# LargeDummyDevice register map
File version: 1.0
Registers are 32-bit, read-write, no defined reset value unless marked. A register's access mark holds for its fields unless they carry their own. Offsets are from the block's base; [hi:lo] are bit positions.

## PERIPHERAL_49
Base 0x40030000
0x04 REG_1 — Register 1
  [32:31] FIELD_6, [30:27] FIELD_8, [30:26] FIELD_1, [27:25] FIELD_3, [27:25] FIELD_4, [27:24] FIELD_5, [7] FIELD_7, [6] FIELD_2
0x08 REG_2 — Register 2
  [32:29] FIELD_25, [28:25] FIELD_4, [27:25] FIELD_26, [24] FIELD_10, [26:24] FIELD_20, [27:23] FIELD_16, [22] FIELD_13, [25:22] FIELD_28, [21] FIELD_7, [20:19] FIELD_1, [22:19] FIELD_23, [21:18] FIELD_18, [20:16] FIELD_9, [19:15] FIELD_22, [12:11] FIELD_27, [11:10] FIELD_5, [12:10] FIELD_8, [11:10] FIELD_15, [9] FIELD_24, [11:7] FIELD_3, [8:5] FIELD_6, [5] FIELD_12, [9:5] FIELD_19, [4:3] FIELD_17, [1] FIELD_11, [4:1] FIELD_14, [2:0] FIELD_2, [1:0] FIELD_21
0x0C REG_3 — Register 3
  [31:30] FIELD_12, [25] FIELD_3, [22:21] FIELD_8, [22:20] FIELD_1, [21:19] FIELD_7, [22:19] FIELD_9, [21:18] FIELD_2, [16:13] FIELD_10, [13:12] FIELD_5, [12:10] FIELD_13, [11:9] FIELD_11, [1] FIELD_4, [4:1] FIELD_6
0x10 REG_4 — Register 4
  [31] FIELD_1, [27] FIELD_8, [29:25] FIELD_6, [25] FIELD_7, [27:24] FIELD_4, [24] FIELD_15, [24:20] FIELD_19, [21:19] FIELD_24, [21:18] FIELD_11, [20:18] FIELD_25, [18:17] FIELD_21, [18:16] FIELD_2, [18:14] FIELD_20, [14:11] FIELD_10, [13:11] FIELD_13, [10] FIELD_16, [10:8] FIELD_3, [9:8] FIELD_5, [11:7] FIELD_9, [8:6] FIELD_12, [9:6] FIELD_17, [6] FIELD_23, [9:5] FIELD_18, [6:2] FIELD_22, [2] FIELD_26, [3:0] FIELD_14
0x14 REG_5 — Register 5
  [32:28] FIELD_4, [29:26] FIELD_2, [27:24] FIELD_3, [13:11] FIELD_5, [12:9] FIELD_6, [9:8] FIELD_7, [0] FIELD_1
0x18 REG_6 — Register 6
  [31] FIELD_7, [34:30] FIELD_3, [30] FIELD_12, [31:27] FIELD_15, [30:27] FIELD_17, [25] FIELD_8, [25:23] FIELD_18, [24:23] FIELD_21, [22:20] FIELD_9, [22:18] FIELD_16, [18:16] FIELD_10, [15] FIELD_19, [14] FIELD_5, [15:13] FIELD_1, [16:12] FIELD_14, [12:10] FIELD_2, [10] FIELD_11, [9:8] FIELD_13, [10:8] FIELD_20, [9:6] FIELD_4, [7:4] FIELD_6
0x1C REG_7 — Register 7
  [35:31] FIELD_12, [32:29] FIELD_11, [25:21] FIELD_2, [24:20] FIELD_4, [22:20] FIELD_6, [18] FIELD_3, [18] FIELD_10, [14:11] FIELD_8, [9] FIELD_7, [10:7] FIELD_1, [4] FIELD_9, [3:1] FIELD_5
0x20 REG_8 — Register 8
  [32:30] FIELD_14, [32:29] FIELD_2, [29:28] FIELD_5, [22] FIELD_7, [23:22] FIELD_23, [23:19] FIELD_20, [22:18] FIELD_13, [20:17] FIELD_1, [16:14] FIELD_10, [14] FIELD_15, [14:13] FIELD_3, [16:13] FIELD_4, [13] FIELD_25, [14:11] FIELD_12, [15:11] FIELD_22, [9] FIELD_16, [11:9] FIELD_17, [12:9] FIELD_19, [11:9] FIELD_24, [9:8] FIELD_21, [7] FIELD_8, [7] FIELD_11, [10:6] FIELD_6, [7:6] FIELD_9, [6:3] FIELD_18
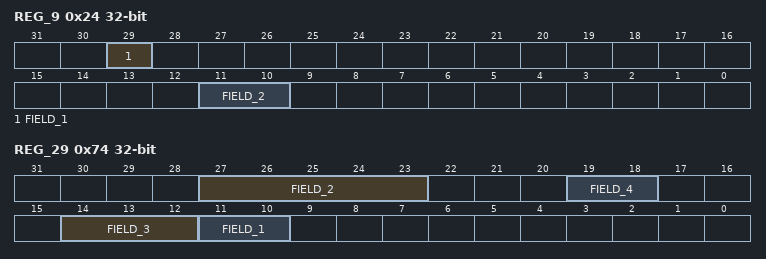
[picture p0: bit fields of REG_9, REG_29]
0x24 REG_9 — Register 9
  [29] FIELD_1, [11:10] FIELD_2
0x28 REG_10 — Register 10
  [34:31] FIELD_21, [30] FIELD_10, [32:30] FIELD_19, [33:29] FIELD_13, [32:28] FIELD_17, [31:27] FIELD_7, [26] FIELD_3, [26] FIELD_4, [26] FIELD_6, [24:23] FIELD_5, [25:22] FIELD_14, [23:21] FIELD_9, [24:21] FIELD_23, [23:21] FIELD_29, [21] FIELD_32, [22:18] FIELD_28, [20:16] FIELD_16, [19:15] FIELD_1, [17:15] FIELD_11, [15:11] FIELD_25, [10] FIELD_27, [13:9] FIELD_8, [10:9] FIELD_30, [9:7] FIELD_26, [7] FIELD_31, [9:6] FIELD_15, [7:6] FIELD_20, [9:5] FIELD_18, [3:2] FIELD_22, [4:2] FIELD_24, [3:0] FIELD_2, [3:0] FIELD_12
0x2C REG_11 — Register 11
  [25:22] FIELD_1
0x30 REG_12 — Register 12
  [26:24] FIELD_2, [27:23] FIELD_3, [23:21] FIELD_5, [17] FIELD_9, [12] FIELD_8, [13:10] FIELD_6, [9] FIELD_4, [11:7] FIELD_7, [8:6] FIELD_1
0x34 REG_13 — Register 13
  [35:31] FIELD_10, [33:30] FIELD_9, [31:30] FIELD_11, [31:29] FIELD_29, [29] FIELD_30, [29:28] FIELD_8, [31:27] FIELD_7, [26:25] FIELD_4, [24:22] FIELD_3, [22] FIELD_6, [23:22] FIELD_25, [17] FIELD_22, [15:14] FIELD_26, [14] FIELD_28, [14:13] FIELD_12, [12] FIELD_31, [15:11] FIELD_23, [13:10] FIELD_1, [13:9] FIELD_16, [10:9] FIELD_19, [9:8] FIELD_5, [9:8] FIELD_13, [7] FIELD_15, [7:5] FIELD_2, [6:5] FIELD_17, [4] FIELD_14, [7:3] FIELD_18, [6:3] FIELD_21, [3] FIELD_27, [3:1] FIELD_24, [0] FIELD_20
0x38 REG_14 — Register 14
  [22] FIELD_4, [15:14] FIELD_3, [13] FIELD_1, [9:7] FIELD_2, [8:6] FIELD_5
0x3C REG_15 — Register 15
  [35:31] FIELD_4, [29] FIELD_16, [23] FIELD_12, [26:22] FIELD_17, [24:21] FIELD_6, [25:21] FIELD_8, [22:21] FIELD_13, [14] FIELD_1, [15:13] FIELD_9, [12] FIELD_7, [14:10] FIELD_10, [7] FIELD_18, [8:6] FIELD_5, [10:6] FIELD_14, [5:4] FIELD_3, [7:3] FIELD_11, [6:3] FIELD_15, [4:2] FIELD_2
0x40 REG_16 — Register 16
  [30:26] FIELD_9, [23:22] FIELD_4, [20:17] FIELD_7, [17:16] FIELD_2, [12] FIELD_8, [13:11] FIELD_1, [11:9] FIELD_6, [8:5] FIELD_5, [4:3] FIELD_11, [3:2] FIELD_3, [2:0] FIELD_10
0x44 REG_17 — Register 17
  [33:31] FIELD_15, [23] FIELD_5, [22:20] FIELD_1, [23:20] FIELD_7, [20:19] FIELD_2, [20:19] FIELD_12, [22:18] FIELD_4, [18:15] FIELD_8, [19:15] FIELD_14, [14] FIELD_6, [17:13] FIELD_9, [13:11] FIELD_13, [10] FIELD_18, [11:10] FIELD_19, [12:10] FIELD_20, [11:9] FIELD_11, [5] FIELD_17, [3] FIELD_3, [4:1] FIELD_10, [3:0] FIELD_16
0x48 REG_18 — Register 18
  [30] FIELD_2, [25] FIELD_3, [23] FIELD_6, [23:22] FIELD_7, [20:19] FIELD_8, [18:17] FIELD_1, [9:6] FIELD_4, [3:1] FIELD_5
0x4C REG_19 — Register 19
  [33:30] FIELD_10, [29:27] FIELD_7, [26] FIELD_2, [29:25] FIELD_5, [12] FIELD_1, [15:12] FIELD_6, [12:8] FIELD_9, [6:5] FIELD_8, [8:4] FIELD_4, [2:1] FIELD_3
0x50 REG_20 — Register 20
  [33:31] FIELD_7, [25:24] FIELD_6, [18] FIELD_8, [19:16] FIELD_1, [11:9] FIELD_10, [10:8] FIELD_2, [6] FIELD_9, [7:4] FIELD_3, [6:3] FIELD_4, [3] FIELD_5, [2] FIELD_12, [3:1] FIELD_11
0x54 REG_21 — Register 21
  [27] FIELD_16, [28:26] FIELD_10, [28:24] FIELD_6, [27:23] FIELD_20, [24:20] FIELD_2, [19] FIELD_9, [19:15] FIELD_3, [15] FIELD_18, [15:14] FIELD_4, [14] FIELD_14, [15:14] FIELD_19, [16:13] FIELD_5, [13:10] FIELD_7, [7:4] FIELD_8, [8:4] FIELD_13, [5:4] FIELD_17, [6:3] FIELD_15, [4:2] FIELD_11, [4:2] FIELD_12, [5:1] FIELD_1
0x58 REG_22 — Register 22
  [34:31] FIELD_21, [30] FIELD_16, [31:29] FIELD_3, [32:29] FIELD_14, [32:28] FIELD_4, [28] FIELD_8, [29:28] FIELD_12, [31:27] FIELD_23, [28:26] FIELD_18, [28:25] FIELD_10, [23] FIELD_15, [25:21] FIELD_7, [22:18] FIELD_9, [20:17] FIELD_22, [17:14] FIELD_19, [17:14] FIELD_24, [14:13] FIELD_6, [14:13] FIELD_17, [13:12] FIELD_13, [15:11] FIELD_20, [8:6] FIELD_5, [6:3] FIELD_11, [2:1] FIELD_1, [1] FIELD_2
0x5C REG_23 — Register 23
  [33:29] FIELD_4, [28:26] FIELD_5, [17:15] FIELD_3, [14:12] FIELD_1, [16:12] FIELD_2
0x60 REG_24 — Register 24
  [29:28] FIELD_10, [29:27] FIELD_9, [27:26] FIELD_4, [28:24] FIELD_11, [23:20] FIELD_5, [16:14] FIELD_6, [2] FIELD_8, [5:1] FIELD_3, [5:1] FIELD_7, [3:0] FIELD_1, [2:0] FIELD_2
0x64 REG_25 — Register 25
  [31:28] FIELD_2, [30:28] FIELD_3, [24:22] FIELD_1, [22:18] FIELD_4
0x68 REG_26 — Register 26
  [30:29] FIELD_9, [29:28] FIELD_7, [29:28] FIELD_26, [29:25] FIELD_16, [24] FIELD_11, [25:24] FIELD_23, [26:23] FIELD_5, [24:23] FIELD_25, [25:23] FIELD_27, [23:21] FIELD_21, [22:20] FIELD_2, [22:20] FIELD_14, [18] FIELD_13, [18:16] FIELD_4, [20:16] FIELD_24, [16] FIELD_30, [19:15] FIELD_6, [17:15] FIELD_10, [18:14] FIELD_3, [13:12] FIELD_12, [16:12] FIELD_19, [15:11] FIELD_15, [15:11] FIELD_29, [13:9] FIELD_22, [10:9] FIELD_28, [11:8] FIELD_17, [9:7] FIELD_18, [6] FIELD_31, [8:4] FIELD_1, [5:1] FIELD_20, [2:0] FIELD_8
0x6C REG_27 — Register 27
  [33:30] FIELD_3, [33:30] FIELD_25, [30:28] FIELD_6, [27:23] FIELD_1, [25:23] FIELD_16, [22:21] FIELD_18, [23:20] FIELD_10, [19] FIELD_12, [20:19] FIELD_21, [18:17] FIELD_2, [18:15] FIELD_11, [17:15] FIELD_20, [17:13] FIELD_4, [14:12] FIELD_13, [15:12] FIELD_22, [13:11] FIELD_17, [12:11] FIELD_19, [10] FIELD_9, [12:10] FIELD_14, [12:9] FIELD_5, [9:5] FIELD_7, [3] FIELD_23, [4:1] FIELD_8, [4:1] FIELD_15, [5:1] FIELD_24
0x70 REG_28 — Register 28
  [32:31] FIELD_9, [34:30] FIELD_7, [32:29] FIELD_13, [28:27] FIELD_11, [28:27] FIELD_14, [22] FIELD_5, [25:21] FIELD_4, [24:21] FIELD_8, [20] FIELD_1, [19:17] FIELD_10, [16] FIELD_12, [16:13] FIELD_3, [9:5] FIELD_6, [1] FIELD_2
0x74 REG_29 — Register 29
  [27:23] FIELD_2, [19:18] FIELD_4, [14:12] FIELD_3, [11:10] FIELD_1
0x78 REG_30 — Register 30
  [27:24] FIELD_2, [21:18] FIELD_6, [15:14] FIELD_4, [17:13] FIELD_3, [10:9] FIELD_5, [10:8] FIELD_1, [10:7] FIELD_7
0x7C REG_31 — Register 31
  [26:22] FIELD_1, [23:19] FIELD_2
0x80 REG_32 — Register 32
  [33:31] FIELD_1, [28] FIELD_5, [25:22] FIELD_3, [14:12] FIELD_7, [13:10] FIELD_4, [9:6] FIELD_2, [0] FIELD_6
0x84 REG_33 — Register 33
  [33:29] FIELD_16, [23:22] FIELD_7, [24:21] FIELD_6, [22:18] FIELD_1, [17] FIELD_14, [17:15] FIELD_11, [16:14] FIELD_4, [17:14] FIELD_5, [11:10] FIELD_3, [14:10] FIELD_13, [6:4] FIELD_10, [4] FIELD_15, [3] FIELD_8, [5:2] FIELD_2, [2] FIELD_9, [4:2] FIELD_12
0x88 REG_34 — Register 34
  [34:30] FIELD_12, [30] FIELD_16, [30:27] FIELD_14, [30:26] FIELD_7, [30:26] FIELD_11, [26:24] FIELD_3, [27:24] FIELD_8, [23] FIELD_10, [21:20] FIELD_5, [14:13] FIELD_4, [13:12] FIELD_9, [14:10] FIELD_1, [13:10] FIELD_17, [10:9] FIELD_13, [8:5] FIELD_15, [1] FIELD_6, [2:0] FIELD_2
